# TC37XPD register map
Vendor: Infineon; Series: ATVMC; File version: 100
CPU: other r0p0, little endian, MPU, FPU, vendor SysTick, 4 interrupt priority bits
Registers are 32-bit, read-write, reset 0x0 unless marked. A register's access mark holds for its fields unless they carry their own. Offsets are from the block's base; [hi:lo] are bit positions; {n}, {i} and the like mark numbered series.

## CAN0 (part 1 of 3) — CAN
Base 0xF0200000
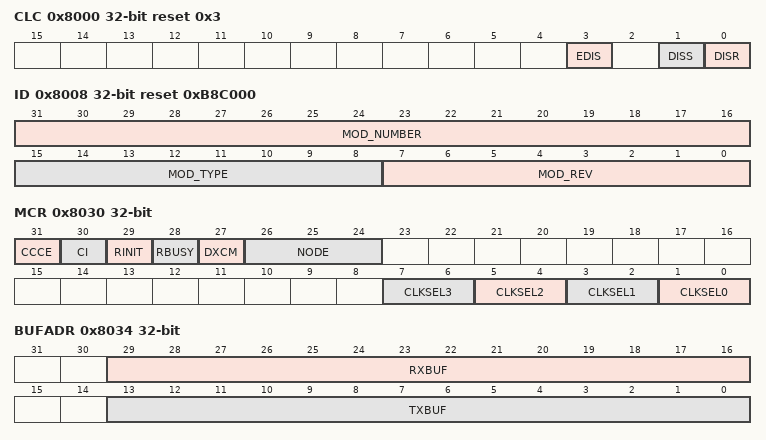
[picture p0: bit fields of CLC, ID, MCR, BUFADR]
0x8000 CLC access per field reset 0x3 — CAN Clock Control Register resetvalue={Application Reset:0x3}
  [3] EDIS rw — Sleep Mode Disable Control EDIS. Used to control module s sleep mode.
  [1] DISS ro — Module Disable Status Bit DISS. Bit indicates the current status of the module.
  [0] DISR rw — Module Disable Request Bit DISR. Used for enable disable control of the module. The synchronous and asynchronous clock is switched on off Note that no register access is possible to any register while module is disabled. A disable request is granted if the M CAN clock is disabled or all M CAN nodes acknowledge the disable request.
0x8008 ID ro reset 0xB8C000 (reset mask 0xFFFFFF00) — Module Identification Register resetvalue={Application Reset:0x0B8C000}
  [31:16] MOD_NUMBER — Module Number Value MOD NUMBER. This bit field defines the MCMCAN module identification number 00B8 .
  [15:8] MOD_TYPE — Module Type MOD TYPE
  [7:0] MOD_REV — Module Revision Number MOD REV. MOD REV defines the revision number. The value of a module revision starts with 01 H first revision .
0x8030 MCR access per field — Module Control Register resetvalue={Application Reset:0x0}
  [31] CCCE rw — Clock and RAM Change Enable CCCE. Needs to be set to enable and disable the clocks.
  [30] CI rw — Change Init CI. Needs to be set to enable and disable clocks.
  [29] RINIT rw — RAM Init RINIT. This bit is not implemented in TC39x A step silicon. This bit is MCR.CI and MCR.CCCE protected. This bit starts the initialization of the RAM block to all 0x0. The RAM initialization is started only when this bit is changed from 0b to 1b and also RBUSY is 0b.
  [28] RBUSY ro — RAM BUSY RBUSY. This bit is not implemented in TC39x A step silicon. This bit shows that the RAM Initialization is running. This bit is set back to 0b by hardware when the RAM intialization is completed.
  [27] DXCM rw — Debug Over CAN Messages Enable DXCM. This bit enables the debug over serial connections between DAP and CAN0 module. If enabled the lowest receive transmit message buffer is reserved for debugger communication. DXCM is described in detail in the OCDS chapter. This bit only exists on CAN0.
  [26:24] NODE rw — Node NODE. This bit field determines the CAN node i which is used for debug over CAN. This bitfield only exists on CAN0.
  [2n+1:2n] CLKSEL{n} rw (n=0..3) — Clock Select {n} CLKSEL{n}. This bitfield is MCR.CI and MCR.CCCE protected.
0x8034 BUFADR — Buffer receive address and transmit address resetvalue={Application Reset:0x0}
  [29:16] RXBUF — Receive Buffer start address RXBUF. This is the start address of the first dedicated receive buffer.
  [13:0] TXBUF — Transmit Buffer start address TXBUF. This is the start address of the first dedicated transmit buffer.
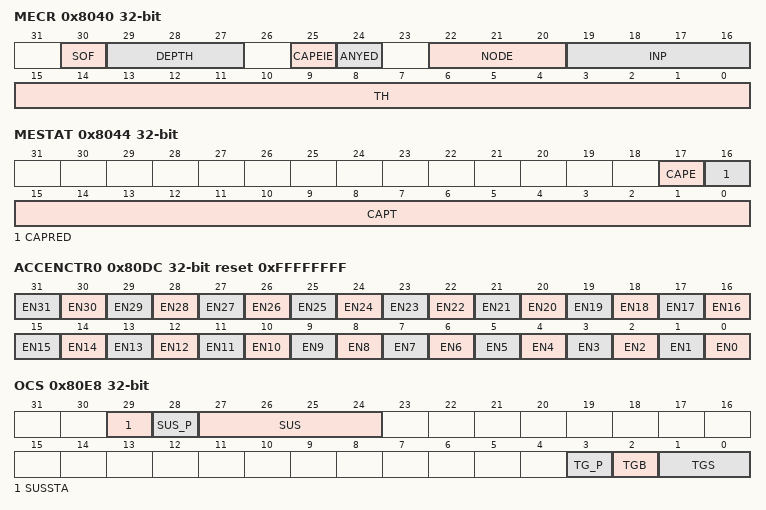
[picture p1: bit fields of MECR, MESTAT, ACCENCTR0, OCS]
0x8040 MECR — Measure Control Register resetvalue={Application Reset:0x0}
  [30] SOF — Start Of Frame SOF. This bit selects falling edge or any edge as measurement for start of frame detection.
  [29:27] DEPTH — Digital Glitch Filter Depth DEPTH. DEPTH determines the number of input samples clocked with f SYNi that are taken into account for the calculation of the floating average. The higher DEPTH is chosen to be the longer the glitches that are suppressed and the longer the delay of the input signal introduced by this filter.
  [25] CAPEIE — Capture Event Interrupt Enable CAPEIE. This bit enables the capture event interrupt. Bit field INP selects the interrupt output line which becomes activated at this type of interrupt.
  [24] ANYED — Any Edge ANYED. This bit enables capture on any edge of CAN input line specified by NODE.
  [22:20] NODE — Node NODE. This bit field determines the CAN node i whose input line RXDCANi is used for start and capture of the measurement timer.
  [19:16] INP — Interrupt Node Pointer INP. INP selects the interrupt output line INT Om m 0 15 for a capture event interrupt.
  [15:0] TH — Threshold TH. This bit field contains the threshold value for the measurement timer. If TH 0000 the timer is stopped and the capture function is disabled.
0x8044 MESTAT access per field — Measure Status Register resetvalue={Application Reset:0x0}
  [17] CAPE rw — Capture Event CAPE. This flag is set on a capture event. It must be reset by software. An interrupt request is generated if MECR.CAPEIE 1. If CAPE 1 then no further measurement results are posted to MESTAT.CAPT and MESTAT.CAPRED. CAPE bit has to be cleared to re enable update of MESTAT.CAPT and MESTAT.CAPRED.
  [16] CAPRED ro — Captured Rising Edge CAPRED. This bit indicates the type of edge that caused the last capture event.
  [15:0] CAPT ro — Captured Timer CAPT. This bit field contains the captured measurement timer content. The timer itself is cleared and started by the first falling dominant edge of a CAN frame on the input line of the CAN node specified by MECR.NODE. The timer is incremented by the module control clock f SYNi and will be stopped when FFFF is reached. If MECR.TH 0000 the timer is always stopped. A capture will take place if all the following conditions are met MECR.TH gt 0000 Timer is cleared and started by new frame Timer reaches MECR.TH This node is not sending and first edge as specified by MECR.ANYED after 3. occurs on input line Capture will be repeated for the following CAN frames until MECR.TH is cleared.
0x80DC ACCENCTR0 reset 0xFFFFFFFF — Access Enable Register Control 0 resetvalue={Application Reset:0x0FFFFFFFF}
  [n] EN{n} (n=0..31) — Access Enable for Master TAG ID 31 EN31. This bit enables write access to the module kernel addresses for transactions with the Master TAG ID y
0x80E8 OCS access per field — OCDS Control and Status resetvalue={Debug Reset:0x0}
  [29] SUSSTA ro — Suspend State SUSSTA
  [28] SUS_P wo — SUS Write Protection SUS P. SUS is only written when SUS P is 1 otherwise unchanged. Read as 0.
  [27:24] SUS rw — OCDS Suspend Control SUS. Controls the sensitivity to the suspend signal coming from the OCDS Trigger Switch OTGS
  [3] TG_P wo — TGS TGB Write Protection TG P. TGS and TGB are only written when TG P is 1 otherwise unchanged. Read as 0.
  [2] TGB rw — OTGB0 1 Bus Select TGB
  [1:0] TGS rw — Trigger Set for OTGB0 1 TGS
0x80EC KRSTCLR wo — Kernel Reset Status Clear Register resetvalue={Application Reset:0x0}
  [0] CLR — Kernel Reset Status Clear CLR. Read always as 0.
0x80F0 KRST1 — Kernel Reset Register 1 resetvalue={Application Reset:0x0}
  [0] RST — Kernel Reset RST. This reset bit can be used to request for a kernel reset. The kernel reset will be executed if the reset bits of both kernel reset registers is set. The RST bit will be cleared reset to 0 by the BPI FPI after the kernel reset was executed.
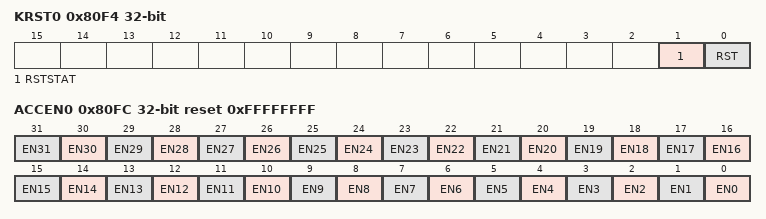
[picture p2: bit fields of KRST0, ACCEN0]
0x80F4 KRST0 access per field — Kernel Reset Register 0 resetvalue={Application Reset:0x0}
  [1] RSTSTAT ro — Kernel Reset Status RSTSTAT. This bit indicates wether a kernel reset was executed or not. This bit is set by the BPI FPI after the execution of a kernel reset in the same clock cycle both reset bits. This bit can be cleared by writing with 180 1 180 to the CLR bit in the related KRSTCLR register.
  [0] RST rw — Kernel Reset RST. This reset bit can be used to request for a kernel reset. The kernel reset will be executed if the reset bits of both kernel registers are set. The RST bit will be cleared reset to 180 0 180 by the BPI FPI after the kernel reset was executed.
0x80FC ACCEN0 reset 0xFFFFFFFF — Access Enable Register 0 resetvalue={Application Reset:0x0FFFFFFFF}
  [n] EN{n} (n=0..31) — Access Enable for Master TAG ID 31 EN31. This bit enables write access to the module kernel addresses for transactions with the Master TAG ID y.
